# STM32F415OGY6 register map
File version: 1.0
Registers are 32-bit, access not given, reset 0x0 unless marked. A register's access mark holds for its fields unless they carry their own. Offsets are from the block's base; [hi:lo] are bit positions; {n}, {i} and the like mark numbered series; 'fields as' and 'values as' point back to an identical list.

## ADC1
Base 0x40012000
Same registers: ADC2 0x40012100, ADC3 0x40012300
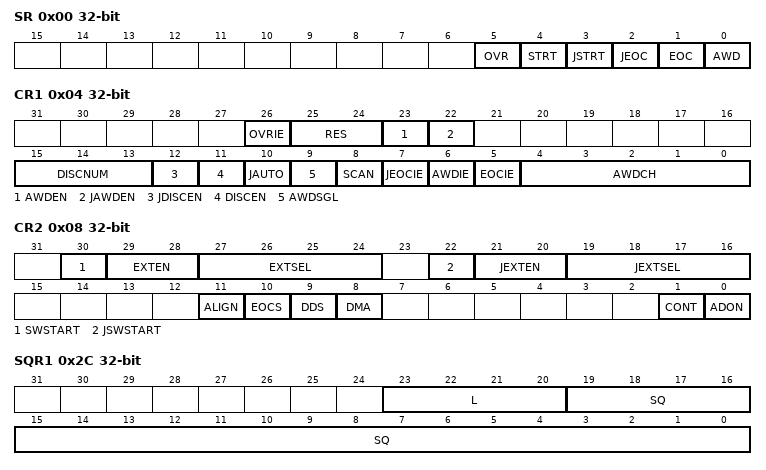
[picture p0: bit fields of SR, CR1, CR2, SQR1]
0x00 SR
  [5] OVR, [4] STRT, [3] JSTRT, [2] JEOC, [1] EOC, [0] AWD
0x04 CR1
  [26] OVRIE, [25:24] RES, [23] AWDEN, [22] JAWDEN, [15:13] DISCNUM, [12] JDISCEN, [11] DISCEN, [10] JAUTO, [9] AWDSGL, [8] SCAN, [7] JEOCIE, [6] AWDIE, [5] EOCIE, [4:0] AWDCH
0x08 CR2
  [30] SWSTART, [29:28] EXTEN, [27:24] EXTSEL, [22] JSWSTART, [21:20] JEXTEN, [19:16] JEXTSEL, [11] ALIGN, [10] EOCS, [9] DDS, [8] DMA, [1] CONT, [0] ADON
0x0C SMPR1
  [31:0] SMP
0x10 SMPR2
  [31:0] SMP
{0x10+4i} JOFR{i} (i=1..4)
  [11:0] JOFFSET{i}
0x24 HTR
  [11:0] HT
0x28 LTR
  [11:0] LT
0x2C SQR1
  [23:20] L, [19:0] SQ
0x30 SQR2
  [29:0] SQ
0x34 SQR3
  [29:0] SQ
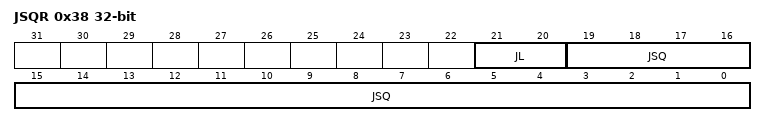
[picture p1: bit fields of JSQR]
0x38 JSQR
  [21:20] JL, [19:0] JSQ
{0x38+4i} JDR{i} (i=1..4)
  [15:0] JDATA
0x4C DR
  [15:0] DATA

## SDIO
Base 0x40012C00
0x00 POWER
  [1:0] PWRCTRL
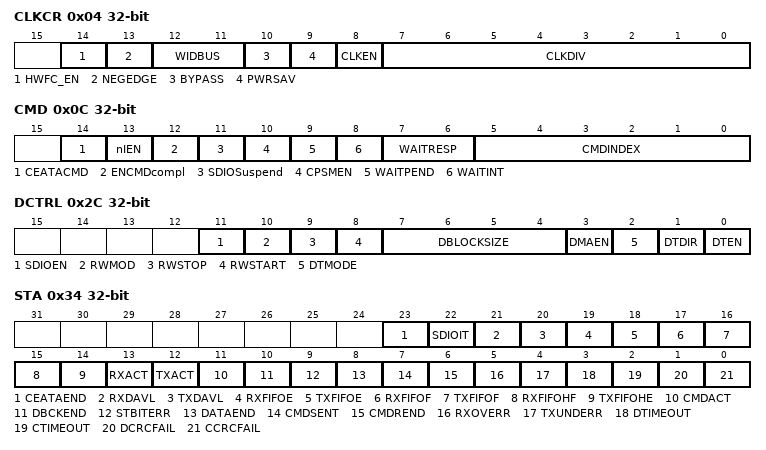
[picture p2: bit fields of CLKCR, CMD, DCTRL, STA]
0x04 CLKCR
  [14] HWFC_EN, [13] NEGEDGE, [12:11] WIDBUS, [10] BYPASS, [9] PWRSAV, [8] CLKEN, [7:0] CLKDIV
0x08 ARG
  [31:0] CMDARG
0x0C CMD
  [14] CEATACMD, [13] nIEN, [12] ENCMDcompl, [11] SDIOSuspend, [10] CPSMEN, [9] WAITPEND, [8] WAITINT, [7:6] WAITRESP, [5:0] CMDINDEX
0x10 RESPCMD
  [5:0] RESPCMD
{0x10+4i} RESP{i} (i=1..4)
  [31:0] CARDSTATUS{i}
0x24 DTIMER
  [31:0] DATATIME
0x28 DLEN
  [24:0] DATALENGTH
0x2C DCTRL
  [11] SDIOEN, [10] RWMOD, [9] RWSTOP, [8] RWSTART, [7:4] DBLOCKSIZE, [3] DMAEN, [2] DTMODE, [1] DTDIR, [0] DTEN
0x30 DCOUNT
  [24:0] DATACOUNT
0x34 STA
  [23] CEATAEND, [22] SDIOIT, [21] RXDAVL, [20] TXDAVL, [19] RXFIFOE, [18] TXFIFOE, [17] RXFIFOF, [16] TXFIFOF, [15] RXFIFOHF, [14] TXFIFOHE, [13] RXACT, [12] TXACT, [11] CMDACT, [10] DBCKEND, [9] STBITERR, [8] DATAEND, [7] CMDSENT, [6] CMDREND, [5] RXOVERR, [4] TXUNDERR, [3] DTIMEOUT, [2] CTIMEOUT, [1] DCRCFAIL, [0] CCRCFAIL
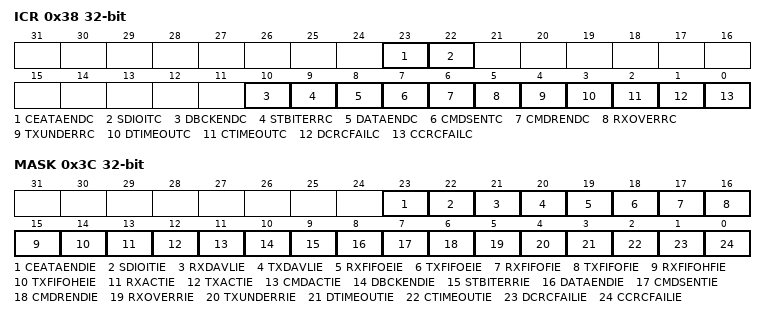
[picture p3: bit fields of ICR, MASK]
0x38 ICR
  [23] CEATAENDC, [22] SDIOITC, [10] DBCKENDC, [9] STBITERRC, [8] DATAENDC, [7] CMDSENTC, [6] CMDRENDC, [5] RXOVERRC, [4] TXUNDERRC, [3] DTIMEOUTC, [2] CTIMEOUTC, [1] DCRCFAILC, [0] CCRCFAILC
0x3C MASK
  [23] CEATAENDIE, [22] SDIOITIE, [21] RXDAVLIE, [20] TXDAVLIE, [19] RXFIFOEIE, [18] TXFIFOEIE, [17] RXFIFOFIE, [16] TXFIFOFIE, [15] RXFIFOHFIE, [14] TXFIFOHEIE, [13] RXACTIE, [12] TXACTIE, [11] CMDACTIE, [10] DBCKENDIE, [9] STBITERRIE, [8] DATAENDIE, [7] CMDSENTIE, [6] CMDRENDIE, [5] RXOVERRIE, [4] TXUNDERRIE, [3] DTIMEOUTIE, [2] CTIMEOUTIE, [1] DCRCFAILIE, [0] CCRCFAILIE
0x48 FIFOCNT
  [23:0] FIFOCOUNT
0x80 FIFO
  [31:0] FIF0Data

## SYSCFG
Base 0x40013800
0x00 MEMRMP
  [1:0] MEM_MODE
0x04 PMC
  [23] MII_RMII_SEL
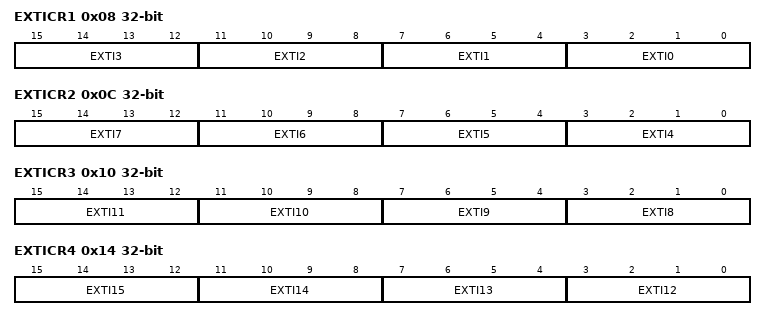
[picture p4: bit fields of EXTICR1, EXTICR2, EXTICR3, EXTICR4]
0x08 EXTICR1
  [4n+3:4n] EXTI{n} (n=0..3)
0x0C EXTICR2
  [4n-13:4n-16] EXTI{n} (n=4..7)
0x10 EXTICR3
  [4n-29:4n-32] EXTI{n} (n=8..11)
0x14 EXTICR4
  [4n-45:4n-48] EXTI{n} (n=12..15)
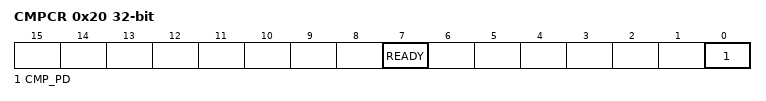
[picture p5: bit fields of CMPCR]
0x20 CMPCR
  [7] READY, [0] CMP_PD

## EXTI
Base 0x40013C00
0x00 IMR
0x04 EMR
0x08 RTSR
0x0C FTSR
0x10 SWIER
0x14 PR

## SAI1
Base 0x40015800
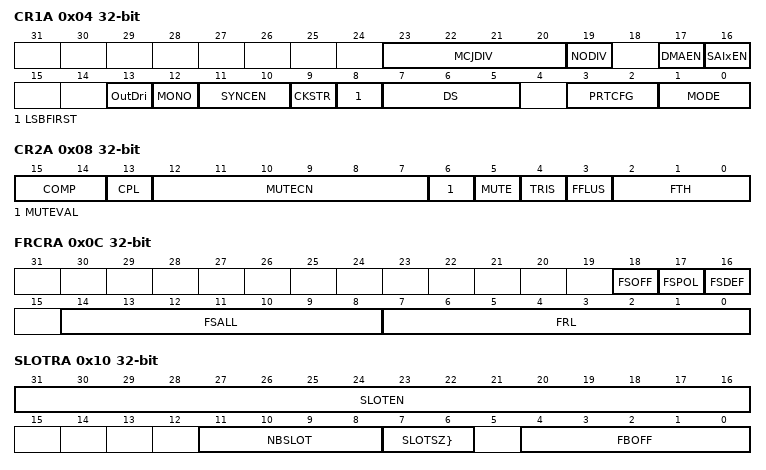
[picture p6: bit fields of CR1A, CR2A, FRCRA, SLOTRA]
0x04 CR1A
  [23:20] MCJDIV, [19] NODIV, [17] DMAEN, [16] SAIxEN, [13] OutDri, [12] MONO, [11:10] SYNCEN, [9] CKSTR, [8] LSBFIRST, [7:5] DS, [3:2] PRTCFG, [1:0] MODE
0x08 CR2A
  [15:14] COMP, [13] CPL, [12:7] MUTECN, [6] MUTEVAL, [5] MUTE, [4] TRIS, [3] FFLUS, [2:0] FTH
0x0C FRCRA
  [18] FSOFF, [17] FSPOL, [16] FSDEF, [14:8] FSALL, [7:0] FRL
0x10 SLOTRA
  [31:16] SLOTEN, [11:8] NBSLOT, [7:6] SLOTSZ}, [4:0] FBOFF
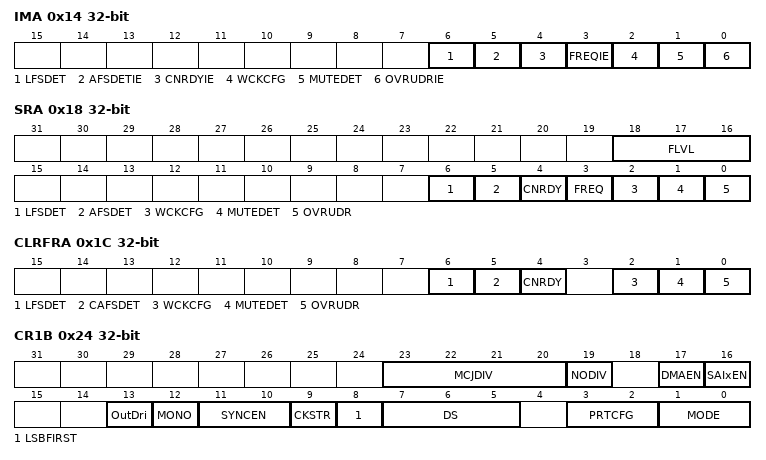
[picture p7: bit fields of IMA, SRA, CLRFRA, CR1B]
0x14 IMA
  [6] LFSDET, [5] AFSDETIE, [4] CNRDYIE, [3] FREQIE, [2] WCKCFG, [1] MUTEDET, [0] OVRUDRIE
0x18 SRA
  [18:16] FLVL, [6] LFSDET, [5] AFSDET, [4] CNRDY, [3] FREQ, [2] WCKCFG, [1] MUTEDET, [0] OVRUDR
0x1C CLRFRA
  [6] LFSDET, [5] CAFSDET, [4] CNRDY, [2] WCKCFG, [1] MUTEDET, [0] OVRUDR
0x20 DRA
  [31:0] DATA
0x24 CR1B
  fields as CR1A
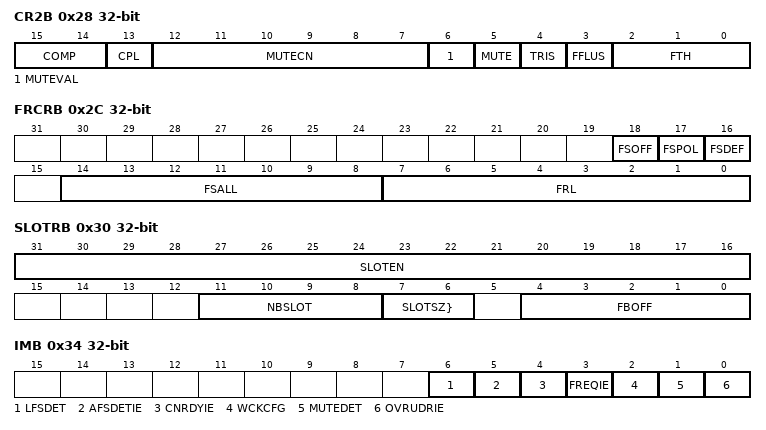
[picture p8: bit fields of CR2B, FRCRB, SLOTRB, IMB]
0x28 CR2B
  fields as CR2A
0x2C FRCRB
  [18] FSOFF, [17] FSPOL, [16] FSDEF, [14:8] FSALL, [7:0] FRL
0x30 SLOTRB
  [31:16] SLOTEN, [11:8] NBSLOT, [7:6] SLOTSZ}, [4:0] FBOFF
0x34 IMB
  fields as IMA
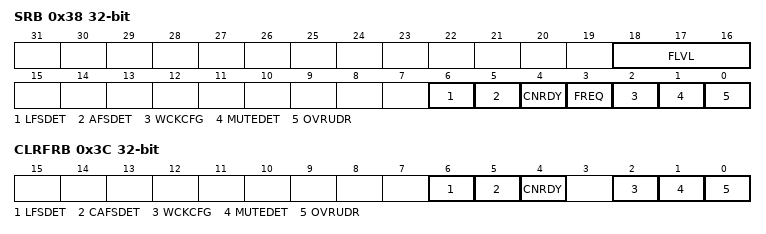
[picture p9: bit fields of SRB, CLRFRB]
0x38 SRB
  fields as SRA
0x3C CLRFRB
  fields as CLRFRA
0x40 DRB
  [31:0] DATA
